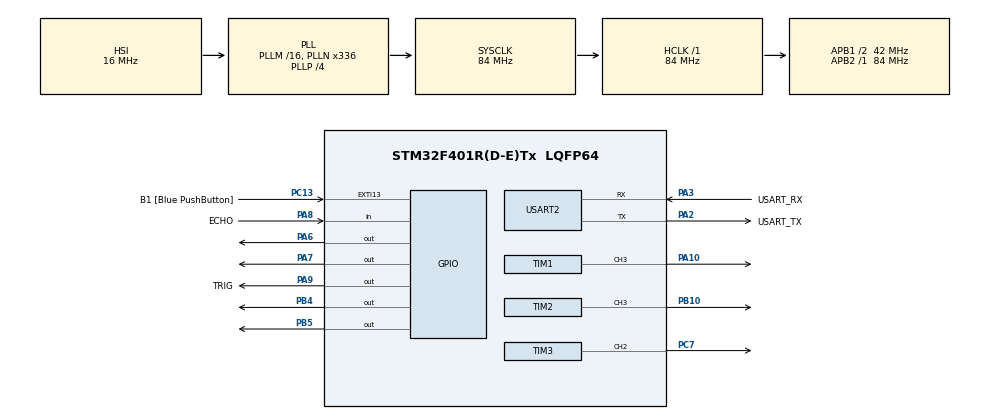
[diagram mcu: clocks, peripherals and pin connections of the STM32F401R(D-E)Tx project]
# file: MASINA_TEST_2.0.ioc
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FREERTOS.Tasks01=defaultTask,24,128,StartDefaultTask,Default,NULL,Dynamic,NULL,NULL
Mcu.Family=STM32F4
Mcu.Name=STM32F401R(D-E)Tx
Mcu.Package=LQFP64
NVIC.PriorityGroup=NVIC_PRIORITYGROUP_4
PA10.Signal=S_TIM1_CH3
PA13.GPIO_Label=TMS
PA13.Mode=Trace_Asynchronous_SW
PA13.Signal=SYS_JTMS-SWDIO
PA14.GPIO_Label=TCK
PA14.Mode=Trace_Asynchronous_SW
PA14.Signal=SYS_JTCK-SWCLK
PA2.GPIO_Label=USART_TX
PA2.GPIO_Mode=GPIO_MODE_AF_PP
PA2.GPIO_PuPd=GPIO_NOPULL
PA2.GPIO_Speed=GPIO_SPEED_FREQ_LOW
PA2.Mode=Asynchronous
PA2.Signal=USART2_TX
PA3.GPIO_Label=USART_RX
PA3.GPIO_Mode=GPIO_MODE_AF_PP
PA3.GPIO_PuPd=GPIO_NOPULL
PA3.GPIO_Speed=GPIO_SPEED_FREQ_LOW
PA3.Mode=Asynchronous
PA3.Signal=USART2_RX
PA6.Signal=GPIO_Output
PA7.Signal=GPIO_Output
PA8.GPIO_Label=ECHO
PA8.Signal=GPIO_Input
PA9.GPIO_Label=TRIG
PA9.Signal=GPIO_Output
PB10.Signal=S_TIM2_CH3
PB3.GPIO_Label=SWO
PB3.Mode=Trace_Asynchronous_SW
PB3.Signal=SYS_JTDO-SWO
PB4.Signal=GPIO_Output
PB5.Signal=GPIO_Output
PC13-ANTI_TAMP.GPIO_Label=B1 [Blue PushButton]
PC13-ANTI_TAMP.GPIO_ModeDefaultEXTI=GPIO_MODE_IT_FALLING
PC13-ANTI_TAMP.GPIO_PuPd=GPIO_NOPULL
PC13-ANTI_TAMP.Signal=GPXTI13
PC14-OSC32_IN.Mode=LSE-External-Oscillator
PC14-OSC32_IN.Signal=RCC_OSC32_IN
PC15-OSC32_OUT.Mode=LSE-External-Oscillator
PC15-OSC32_OUT.Signal=RCC_OSC32_OUT
PC7.Signal=S_TIM3_CH2
PH0\ -\ OSC_IN.Mode=HSE-External-Clock-Source
PH0\ -\ OSC_IN.Signal=RCC_OSC_IN
PH1\ -\ OSC_OUT.Mode=HSE-External-Clock-Source
PH1\ -\ OSC_OUT.Signal=RCC_OSC_OUT
ProjectManager.HeapSize=0x200
ProjectManager.StackSize=0x400
ProjectManager.TargetToolchain=STM32CubeIDE
RCC.48MHZClocksFreq_Value=48000000
RCC.AHBFreq_Value=84000000
RCC.APB1CLKDivider=RCC_HCLK_DIV2
RCC.APB1Freq_Value=42000000
RCC.APB1TimFreq_Value=84000000
RCC.APB2Freq_Value=84000000
RCC.APB2TimFreq_Value=84000000
RCC.CortexFreq_Value=84000000
RCC.HCLKFreq_Value=84000000
RCC.HSE_VALUE=8000000
RCC.HSI_VALUE=16000000
RCC.PLLN=336
RCC.PLLP=RCC_PLLP_DIV4
RCC.PLLQ=7
RCC.SYSCLKFreq_VALUE=84000000
RCC.SYSCLKSource=RCC_SYSCLKSOURCE_PLLCLK
RCC.VCOOutputFreq_Value=336000000
SH.S_TIM1_CH3.0=TIM1_CH3,PWM Generation3 CH3
SH.S_TIM2_CH3.0=TIM2_CH3,PWM Generation3 CH3
SH.S_TIM3_CH2.0=TIM3_CH2,PWM Generation2 CH2
TIM1.Channel-PWM\ Generation3\ CH3=TIM_CHANNEL_3
TIM1.Period=4199
TIM2.Channel-PWM\ Generation3\ CH3=TIM_CHANNEL_3
TIM2.Period=4199
TIM3.Channel-PWM\ Generation2\ CH2=TIM_CHANNEL_2
TIM3.Period=19999
TIM3.Prescaler=83
TIM4.Period=0
TIM4.Prescaler=83
USART2.VirtualMode=VM_ASYNC
VP_FREERTOS_VS_CMSIS_V2.Mode=CMSIS_V2
VP_TIM1_VS_ClockSourceINT.Mode=Internal
VP_TIM2_VS_ClockSourceINT.Mode=Internal
VP_TIM3_VS_ClockSourceINT.Mode=Internal
VP_TIM4_VS_ClockSourceINT.Mode=Internal
board=NUCLEO-F401RE

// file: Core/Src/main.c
/* USER CODE BEGIN Header */
/**
  ******************************************************************************
  * @file           : main.c
  * @brief          : Main program body
  ******************************************************************************
  * @attention
  *
  * Copyright (c) 2025 STMicroelectronics.
  * All rights reserved.
  *
  * This software is licensed under terms that can be found in the LICENSE file
  * in the root directory of this software component.
  * If no LICENSE file comes with this software, it is provided AS-IS.
  *
  ******************************************************************************
  */
/* USER CODE END Header */
#include "main.h"
#include "cmsis_os.h"
#include <string.h>
#include <stdio.h>
/* USER CODE BEGIN Includes */
#define usTIM	TIM4
/* USER CODE END Includes */

TIM_HandleTypeDef htim1;
TIM_HandleTypeDef htim2;

TIM_HandleTypeDef htim3;

TIM_HandleTypeDef htim4;

UART_HandleTypeDef huart2;

/* Definitions for defaultTask */
osThreadId_t defaultTaskHandle;
const osThreadAttr_t defaultTask_attributes = {
  .name = "defaultTask",
  .stack_size = 128 * 4,
  .priority = (osPriority_t) osPriorityNormal,
};

void SystemClock_Config(void);
static void MX_GPIO_Init(void);
static void MX_USART2_UART_Init(void);
static void MX_TIM4_Init(void);
static void MX_TIM3_Init(void);
static void MX_TIM2_Init(void);
static void MX_TIM1_Init(void);

void left(void);
void Right(void);
uint8_t ScanServoForClearPath();
void back(void);
void StartMotors(void);
void stopMotors(void);
float Measure_Distance(void);
void StartDefaultTask(void *argument);
//void DC_Motors(void);
/* USER CODE BEGIN PFP */
void usDelay(uint32_t uSec);
/* USER CODE END PFP */

/* USER CODE BEGIN 0 */
const float speedOfSound = 0.0343/2;
float distance;
uint32_t numTicks = 0;
char uartBuf[100];
/* USER CODE END 0 */

int main(void)
{

  /* MCU Configuration--------------------------------------------------------*/

  /* Reset of all peripherals, Initializes the Flash interface and the Systick. */
  HAL_Init();

  /* Configure the system clock */
  SystemClock_Config();

  /* Initialize all configured peripherals */
  MX_GPIO_Init();
  MX_USART2_UART_Init();
  MX_TIM4_Init();
  MX_TIM3_Init();
  MX_TIM2_Init();
  MX_TIM1_Init();
  /* USER CODE BEGIN 2 */

    HAL_TIM_PWM_Start(&htim3,TIM_CHANNEL_2);

    HAL_TIM_PWM_Start(&htim1,TIM_CHANNEL_3);
    HAL_TIM_PWM_Start(&htim2,TIM_CHANNEL_3);
  /* USER CODE END 2 */

  /* Init scheduler */
  osKernelInitialize();

  /* Create the thread(s) */
  /* creation of defaultTask */
  defaultTaskHandle = osThreadNew(StartDefaultTask, NULL, &defaultTask_attributes);

  /* Start scheduler */
  osKernelStart();

  /* We should never get here as control is now taken by the scheduler */

  /* Infinite loop */
  /* USER CODE BEGIN WHILE */
//  while (1)
//  {
    /* USER CODE END WHILE */

    /* USER CODE BEGIN 3 */
//  }
  /* USER CODE END 3 */
}

void SystemClock_Config(void)
{
  RCC_OscInitTypeDef RCC_OscInitStruct = {0};
  RCC_ClkInitTypeDef RCC_ClkInitStruct = {0};

  /** Configure the main internal regulator output voltage
  */
  __HAL_RCC_PWR_CLK_ENABLE();
  __HAL_PWR_VOLTAGESCALING_CONFIG(PWR_REGULATOR_VOLTAGE_SCALE2);

  /** Initializes the RCC Oscillators according to the specified parameters
  * in the RCC_OscInitTypeDef structure.
  */
  RCC_OscInitStruct.OscillatorType = RCC_OSCILLATORTYPE_HSI;
  RCC_OscInitStruct.HSIState = RCC_HSI_ON;
  RCC_OscInitStruct.HSICalibrationValue = RCC_HSICALIBRATION_DEFAULT;
  RCC_OscInitStruct.PLL.PLLState = RCC_PLL_ON;
  RCC_OscInitStruct.PLL.PLLSource = RCC_PLLSOURCE_HSI;
  RCC_OscInitStruct.PLL.PLLM = 16;
  RCC_OscInitStruct.PLL.PLLN = 336;
  RCC_OscInitStruct.PLL.PLLP = RCC_PLLP_DIV4;
  RCC_OscInitStruct.PLL.PLLQ = 7;
  if (HAL_RCC_OscConfig(&RCC_OscInitStruct) != HAL_OK)
  {
    Error_Handler();
  }

  /** Initializes the CPU, AHB and APB buses clocks
  */
  RCC_ClkInitStruct.ClockType = RCC_CLOCKTYPE_HCLK|RCC_CLOCKTYPE_SYSCLK
                              |RCC_CLOCKTYPE_PCLK1|RCC_CLOCKTYPE_PCLK2;
  RCC_ClkInitStruct.SYSCLKSource = RCC_SYSCLKSOURCE_PLLCLK;
  RCC_ClkInitStruct.AHBCLKDivider = RCC_SYSCLK_DIV1;
  RCC_ClkInitStruct.APB1CLKDivider = RCC_HCLK_DIV2;
  RCC_ClkInitStruct.APB2CLKDivider = RCC_HCLK_DIV1;

  if (HAL_RCC_ClockConfig(&RCC_ClkInitStruct, FLASH_LATENCY_2) != HAL_OK)
  {
    Error_Handler();
  }
}

static void MX_TIM1_Init(void)
{

  TIM_ClockConfigTypeDef sClockSourceConfig = {0};
  TIM_MasterConfigTypeDef sMasterConfig = {0};
  TIM_OC_InitTypeDef sConfigOC = {0};
  TIM_BreakDeadTimeConfigTypeDef sBreakDeadTimeConfig = {0};

  htim1.Instance = TIM1;
  htim1.Init.Prescaler = 89;
  htim1.Init.CounterMode = TIM_COUNTERMODE_UP;
  htim1.Init.Period = 1999;
  htim1.Init.ClockDivision = TIM_CLOCKDIVISION_DIV1;
  htim1.Init.RepetitionCounter = 0;
  htim1.Init.AutoReloadPreload = TIM_AUTORELOAD_PRELOAD_DISABLE;
  if (HAL_TIM_Base_Init(&htim1) != HAL_OK)
  {
    Error_Handler();
  }
  sClockSourceConfig.ClockSource = TIM_CLOCKSOURCE_INTERNAL;
  if (HAL_TIM_ConfigClockSource(&htim1, &sClockSourceConfig) != HAL_OK)
  {
    Error_Handler();
  }
  if (HAL_TIM_PWM_Init(&htim1) != HAL_OK)
  {
    Error_Handler();
  }
  sMasterConfig.MasterOutputTrigger = TIM_TRGO_RESET;
  sMasterConfig.MasterSlaveMode = TIM_MASTERSLAVEMODE_DISABLE;
  if (HAL_TIMEx_MasterConfigSynchronization(&htim1, &sMasterConfig) != HAL_OK)
  {
    Error_Handler();
  }
  sConfigOC.OCMode = TIM_OCMODE_PWM1;
  sConfigOC.Pulse = 0;
  sConfigOC.OCPolarity = TIM_OCPOLARITY_HIGH;
  sConfigOC.OCNPolarity = TIM_OCNPOLARITY_HIGH;
  sConfigOC.OCFastMode = TIM_OCFAST_DISABLE;
  sConfigOC.OCIdleState = TIM_OCIDLESTATE_RESET;
  sConfigOC.OCNIdleState = TIM_OCNIDLESTATE_RESET;
  if (HAL_TIM_PWM_ConfigChannel(&htim1, &sConfigOC, TIM_CHANNEL_3) != HAL_OK)
  {
    Error_Handler();
  }
  sBreakDeadTimeConfig.OffStateRunMode = TIM_OSSR_DISABLE;
  sBreakDeadTimeConfig.OffStateIDLEMode = TIM_OSSI_DISABLE;
  sBreakDeadTimeConfig.LockLevel = TIM_LOCKLEVEL_OFF;
  sBreakDeadTimeConfig.DeadTime = 0;
  sBreakDeadTimeConfig.BreakState = TIM_BREAK_DISABLE;
  sBreakDeadTimeConfig.BreakPolarity = TIM_BREAKPOLARITY_HIGH;
  sBreakDeadTimeConfig.AutomaticOutput = TIM_AUTOMATICOUTPUT_DISABLE;
  if (HAL_TIMEx_ConfigBreakDeadTime(&htim1, &sBreakDeadTimeConfig) != HAL_OK)
  {
    Error_Handler();
  }
  HAL_TIM_MspPostInit(&htim1);

}

static void MX_TIM2_Init(void)
{

  TIM_ClockConfigTypeDef sClockSourceConfig = {0};
  TIM_MasterConfigTypeDef sMasterConfig = {0};
  TIM_OC_InitTypeDef sConfigOC = {0};

  htim2.Instance = TIM2;
  htim2.Init.Prescaler = 89;
  htim2.Init.CounterMode = TIM_COUNTERMODE_UP;
  htim2.Init.Period = 1999;
  htim2.Init.ClockDivision = TIM_CLOCKDIVISION_DIV1;
  htim2.Init.AutoReloadPreload = TIM_AUTORELOAD_PRELOAD_DISABLE;
  if (HAL_TIM_Base_Init(&htim2) != HAL_OK)
  {
    Error_Handler();
  }
  sClockSourceConfig.ClockSource = TIM_CLOCKSOURCE_INTERNAL;
  if (HAL_TIM_ConfigClockSource(&htim2, &sClockSourceConfig) != HAL_OK)
  {
    Error_Handler();
  }
  if (HAL_TIM_PWM_Init(&htim2) != HAL_OK)
  {
    Error_Handler();
  }
  sMasterConfig.MasterOutputTrigger = TIM_TRGO_RESET;
  sMasterConfig.MasterSlaveMode = TIM_MASTERSLAVEMODE_DISABLE;
  if (HAL_TIMEx_MasterConfigSynchronization(&htim2, &sMasterConfig) != HAL_OK)
  {
    Error_Handler();
  }
  sConfigOC.OCMode = TIM_OCMODE_PWM1;
  sConfigOC.Pulse = 0;
  sConfigOC.OCPolarity = TIM_OCPOLARITY_HIGH;
  sConfigOC.OCFastMode = TIM_OCFAST_DISABLE;
  if (HAL_TIM_PWM_ConfigChannel(&htim2, &sConfigOC, TIM_CHANNEL_3) != HAL_OK)
  {
    Error_Handler();
  }
  HAL_TIM_MspPostInit(&htim2);

}

static void MX_TIM3_Init(void)
{

  TIM_ClockConfigTypeDef sClockSourceConfig = {0};
  TIM_MasterConfigTypeDef sMasterConfig = {0};
  TIM_OC_InitTypeDef sConfigOC = {0};

  htim3.Instance = TIM3;
  htim3.Init.Prescaler = 83;
  htim3.Init.CounterMode = TIM_COUNTERMODE_UP;
  htim3.Init.Period = 19999;
  htim3.Init.ClockDivision = TIM_CLOCKDIVISION_DIV1;
  htim3.Init.AutoReloadPreload = TIM_AUTORELOAD_PRELOAD_DISABLE;
  if (HAL_TIM_Base_Init(&htim3) != HAL_OK)
  {
    Error_Handler();
  }
  sClockSourceConfig.ClockSource = TIM_CLOCKSOURCE_INTERNAL;
  if (HAL_TIM_ConfigClockSource(&htim3, &sClockSourceConfig) != HAL_OK)
  {
    Error_Handler();
  }
  if (HAL_TIM_PWM_Init(&htim3) != HAL_OK)
  {
    Error_Handler();
  }
  sMasterConfig.MasterOutputTrigger = TIM_TRGO_RESET;
  sMasterConfig.MasterSlaveMode = TIM_MASTERSLAVEMODE_DISABLE;
  if (HAL_TIMEx_MasterConfigSynchronization(&htim3, &sMasterConfig) != HAL_OK)
  {
    Error_Handler();
  }
  sConfigOC.OCMode = TIM_OCMODE_PWM1;
  sConfigOC.Pulse = 0;
  sConfigOC.OCPolarity = TIM_OCPOLARITY_HIGH;
  sConfigOC.OCFastMode = TIM_OCFAST_DISABLE;
  if (HAL_TIM_PWM_ConfigChannel(&htim3, &sConfigOC, TIM_CHANNEL_2) != HAL_OK)
  {
    Error_Handler();
  }
  HAL_TIM_MspPostInit(&htim3);

}

static void MX_TIM4_Init(void)
{

  TIM_ClockConfigTypeDef sClockSourceConfig = {0};
  TIM_MasterConfigTypeDef sMasterConfig = {0};

  htim4.Instance = TIM4;
  htim4.Init.Prescaler = 83;
  htim4.Init.CounterMode = TIM_COUNTERMODE_UP;
  htim4.Init.Period = 0;
  htim4.Init.ClockDivision = TIM_CLOCKDIVISION_DIV1;
  htim4.Init.AutoReloadPreload = TIM_AUTORELOAD_PRELOAD_DISABLE;
  if (HAL_TIM_Base_Init(&htim4) != HAL_OK)
  {
    Error_Handler();
  }
  sClockSourceConfig.ClockSource = TIM_CLOCKSOURCE_INTERNAL;
  if (HAL_TIM_ConfigClockSource(&htim4, &sClockSourceConfig) != HAL_OK)
  {
    Error_Handler();
  }
  sMasterConfig.MasterOutputTrigger = TIM_TRGO_RESET;
  sMasterConfig.MasterSlaveMode = TIM_MASTERSLAVEMODE_DISABLE;
  if (HAL_TIMEx_MasterConfigSynchronization(&htim4, &sMasterConfig) != HAL_OK)
  {
    Error_Handler();
  }

}

static void MX_USART2_UART_Init(void)
{

  huart2.Instance = USART2;
  huart2.Init.BaudRate = 115200;
  huart2.Init.WordLength = UART_WORDLENGTH_8B;
  huart2.Init.StopBits = UART_STOPBITS_1;
  huart2.Init.Parity = UART_PARITY_NONE;
  huart2.Init.Mode = UART_MODE_TX_RX;
  huart2.Init.HwFlowCtl = UART_HWCONTROL_NONE;
  huart2.Init.OverSampling = UART_OVERSAMPLING_16;
  if (HAL_UART_Init(&huart2) != HAL_OK)
  {
    Error_Handler();
  }

}

static void MX_GPIO_Init(void)
{
  GPIO_InitTypeDef GPIO_InitStruct = {0};

  /* GPIO Ports Clock Enable */
  __HAL_RCC_GPIOC_CLK_ENABLE();
  __HAL_RCC_GPIOH_CLK_ENABLE();
  __HAL_RCC_GPIOA_CLK_ENABLE();
  __HAL_RCC_GPIOB_CLK_ENABLE();

  /*Configure GPIO pin Output Level */
  HAL_GPIO_WritePin(GPIOA, GPIO_PIN_6|GPIO_PIN_7|TRIG_Pin, GPIO_PIN_RESET);

  /*Configure GPIO pin Output Level */
  HAL_GPIO_WritePin(GPIOB, GPIO_PIN_4|GPIO_PIN_5, GPIO_PIN_RESET);

  /*Configure GPIO pin : B1_Pin */
  GPIO_InitStruct.Pin = B1_Pin;
  GPIO_InitStruct.Mode = GPIO_MODE_IT_FALLING;
  GPIO_InitStruct.Pull = GPIO_NOPULL;
  HAL_GPIO_Init(B1_GPIO_Port, &GPIO_InitStruct);

  /*Configure GPIO pins : PA6 PA7 TRIG_Pin */
  GPIO_InitStruct.Pin = GPIO_PIN_6|GPIO_PIN_7|TRIG_Pin;
  GPIO_InitStruct.Mode = GPIO_MODE_OUTPUT_PP;
  GPIO_InitStruct.Pull = GPIO_NOPULL;
  GPIO_InitStruct.Speed = GPIO_SPEED_FREQ_LOW;
  HAL_GPIO_Init(GPIOA, &GPIO_InitStruct);

  /*Configure GPIO pin : ECHO_Pin */
  GPIO_InitStruct.Pin = ECHO_Pin;
  GPIO_InitStruct.Mode = GPIO_MODE_INPUT;
  GPIO_InitStruct.Pull = GPIO_NOPULL;
  HAL_GPIO_Init(ECHO_GPIO_Port, &GPIO_InitStruct);

  /*Configure GPIO pins : PB4 PB5 */
  GPIO_InitStruct.Pin = GPIO_PIN_4|GPIO_PIN_5;
  GPIO_InitStruct.Mode = GPIO_MODE_OUTPUT_PP;
  GPIO_InitStruct.Pull = GPIO_NOPULL;
  GPIO_InitStruct.Speed = GPIO_SPEED_FREQ_LOW;
  HAL_GPIO_Init(GPIOB, &GPIO_InitStruct);

}

/* ===========================
 * USER-CREATED FUNCTIONS WITH COMMENTS
 * ===========================*/

/*===========================================================
 * SetServoAngle
 * Sets the servo motor angle (0° to 180°) by adjusting the PWM pulse width.
 *===========================================================*/
void SetServoAngle(uint8_t angle)
{
    // Calculate PWM pulse width based on desired servo angle.
    // Formula: Start at 1000us (0°), add proportionally up to 2000us (180°).
    uint16_t pulse = 1000 + (angle * 1000) / 180;

    // Set PWM duty cycle for TIM3 Channel 2 to move the servo.
    __HAL_TIM_SET_COMPARE(&htim3, TIM_CHANNEL_2, pulse);
}

/*===========================================================
 * usDelay
 * Creates a microsecond-level delay using a hardware timer (TIM4).
 *===========================================================*/
void usDelay(uint32_t uSec)
{
    if(uSec < 2) uSec = 2;  // Minimum delay of 2µs to avoid instability.

    // Load Auto-Reload Register (ARR) with delay ticks.
    usTIM->ARR = uSec - 1;

    // Wait until the update flag (UIF) is set by the timer.
    while((usTIM->SR & 0x0001) != 1);

    // Clear the UIF flag for next use.
    usTIM->SR &= ~(0x0001);
}

/*===========================================================
 * Measure_Distance
 * Uses an HC-SR04 ultrasonic sensor to measure distance.
 * Sends a 10µs pulse on TRIG and measures the HIGH pulse width on ECHO.
 * Returns distance in centimeters.
 *===========================================================*/
float Measure_Distance(void)
{
    // Ensure TRIG is LOW before starting.
    HAL_GPIO_WritePin(TRIG_GPIO_Port, TRIG_Pin, GPIO_PIN_RESET);
    usDelay(3);  // Short delay for stability.

    // Send a HIGH pulse on TRIG for 10µs to trigger measurement.
    HAL_GPIO_WritePin(TRIG_GPIO_Port, TRIG_Pin, GPIO_PIN_SET);
    usDelay(10);
    HAL_GPIO_WritePin(TRIG_GPIO_Port, TRIG_Pin, GPIO_PIN_RESET);

    // Wait until ECHO goes HIGH (sound wave detected).
    while(HAL_GPIO_ReadPin(ECHO_GPIO_Port, ECHO_Pin) == GPIO_PIN_RESET);

    // Measure how long ECHO stays HIGH (time of flight).
    numTicks = 0;
    while(HAL_GPIO_ReadPin(ECHO_GPIO_Port, ECHO_Pin) == GPIO_PIN_SET)
    {
        numTicks++;
        usDelay(2);  // Each loop ~2.8µs (depends on timer speed).
    }

    // Convert measured time to distance: time * speed of sound (cm/µs).
    distance = (numTicks + 0.0f) * 2.8 * speedOfSound;

    return distance;
}

/*===========================================================
 * StartMotors
 * Runs both DC motors forward at a set speed using PWM.
 *===========================================================*/
void StartMotors()
{
    // Left motor forward: IN1=1, IN2=0
    HAL_GPIO_WritePin(GPIOB, GPIO_PIN_4, 1);
    HAL_GPIO_WritePin(GPIOB, GPIO_PIN_5, 0);
    __HAL_TIM_SET_COMPARE(&htim2, TIM_CHANNEL_3, 1000); // PWM duty for speed

    // Right motor forward: IN3=1, IN4=0
    HAL_GPIO_WritePin(GPIOA, GPIO_PIN_6, 1);
    HAL_GPIO_WritePin(GPIOA, GPIO_PIN_7, 0);
    __HAL_TIM_SET_COMPARE(&htim1, TIM_CHANNEL_3, 1000); // PWM duty for speed
}

/*===========================================================
 * stopMotors
 * Stops both DC motors by disabling all H-bridge inputs.
 *===========================================================*/
void stopMotors()
{
    // Set all motor control pins to LOW → stop movement
    HAL_GPIO_WritePin(GPIOB, GPIO_PIN_4, 0);
    HAL_GPIO_WritePin(GPIOB, GPIO_PIN_5, 0);
    HAL_GPIO_WritePin(GPIOA, GPIO_PIN_6, 0);
    HAL_GPIO_WritePin(GPIOA, GPIO_PIN_7, 0);
}

/*===========================================================
 * back
 * Moves the robot backward by reversing both motors.
 *===========================================================*/
void back()
{
    // Left motor reverse: IN1=0, IN2=1
    HAL_GPIO_WritePin(GPIOB, GPIO_PIN_4, 0);
    HAL_GPIO_WritePin(GPIOB, GPIO_PIN_5, 1);
    __HAL_TIM_SET_COMPARE(&htim2, TIM_CHANNEL_3, 900); // PWM duty

    // Right motor reverse: IN3=0, IN4=1
    HAL_GPIO_WritePin(GPIOA, GPIO_PIN_6, 0);
    HAL_GPIO_WritePin(GPIOA, GPIO_PIN_7, 1);
    __HAL_TIM_SET_COMPARE(&htim1, TIM_CHANNEL_3, 900); // PWM duty
}

/*===========================================================
 * Right
 * Spins motors in opposite directions to turn robot right.
 *===========================================================*/
void Right()
{
    // Left motor forward
    HAL_GPIO_WritePin(GPIOB, GPIO_PIN_4, 1);
    HAL_GPIO_WritePin(GPIOB, GPIO_PIN_5, 0);
    __HAL_TIM_SET_COMPARE(&htim2, TIM_CHANNEL_3, 900);

    // Right motor reverse
    HAL_GPIO_WritePin(GPIOA, GPIO_PIN_6, 0);
    HAL_GPIO_WritePin(GPIOA, GPIO_PIN_7, 1);
    __HAL_TIM_SET_COMPARE(&htim1, TIM_CHANNEL_3, 900);
}

/*===========================================================
 * left
 * Spins motors in opposite directions to turn robot left.
 *===========================================================*/
void left()
{
    // Left motor reverse
    HAL_GPIO_WritePin(GPIOB, GPIO_PIN_4, 0);
    HAL_GPIO_WritePin(GPIOB, GPIO_PIN_5, 1);
    __HAL_TIM_SET_COMPARE(&htim2, TIM_CHANNEL_3, 900);

    // Right motor forward
    HAL_GPIO_WritePin(GPIOA, GPIO_PIN_6, 1);
    HAL_GPIO_WritePin(GPIOA, GPIO_PIN_7, 0);
    __HAL_TIM_SET_COMPARE(&htim1, TIM_CHANNEL_3, 900);
}

/*===========================================================
 * ScanServoForClearPath
 * Rotates the servo left and right, measures distances,
 * and returns the best angle for obstacle avoidance.
 *===========================================================*/
uint8_t ScanServoForClearPath()
{
    float currentDistance;
    float maxDistance = 0;
    uint8_t bestAngle = 90; // Default forward direction

    // Sweep servo from 90° to 180° (right side)
    for (uint8_t angle = 90; angle <= 180; angle += 10)
    {
        SetServoAngle(angle);
        HAL_Delay(100); // Wait for servo
        currentDistance = Measure_Distance();

        if (currentDistance > maxDistance)
        {
            maxDistance = currentDistance;
            bestAngle = angle;  // Store best direction
        }
    }

    // Sweep servo back from 180° to 0° (left side)
    for (uint8_t angle = 180; angle >= 10; angle -= 10)
    {
        SetServoAngle(angle);
        HAL_Delay(100);
        currentDistance = Measure_Distance();

        if (currentDistance > maxDistance)
        {
            maxDistance = currentDistance;
            bestAngle = angle;
        }
    }

    // Send debug info via UART for testing
    sprintf(uartBuf, "Distance: %.2f, Max: %.2f, BestAngle: %d\r\n", currentDistance, maxDistance, bestAngle);
    HAL_UART_Transmit(&huart2, (uint8_t *)uartBuf, strlen(uartBuf), 100);

    return bestAngle;
}

/*===========================================================
 * StartDefaultTask
 * Main FreeRTOS task running obstacle avoidance loop.
 *===========================================================*/
void StartDefaultTask(void *argument)
{
    for(;;)
    {
        // Check if obstacle is closer than 10 cm
        if (Measure_Distance() < 10)
        {
            back();        // Move backwards briefly
            HAL_Delay(500);

            stopMotors();  // Stop completely
            HAL_Delay(1000);

            // Scan environment for best angle
            int8_t bestAngle = ScanServoForClearPath();

            // Center the servo again
            SetServoAngle(90);
            HAL_Delay(200);

            // Decide turning direction
            if (bestAngle <= 20)
            {
                left();          // Turn left
                HAL_Delay(500);
                stopMotors();
            }
            else if (bestAngle >= 25)
            {
                Right();         // Turn right
                HAL_Delay(500);
                stopMotors();
            }
        }
        else
        {
            StartMotors(); // Path is clear → move forward
        }
    }
}

void Error_Handler(void)
{
  __disable_irq();
  while (1)
  {
  }
}
